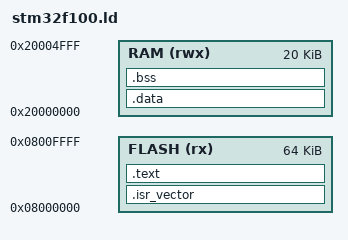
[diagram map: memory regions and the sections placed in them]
ENTRY(Reset_Handler)

MEMORY
{
  FLASH (rx) : ORIGIN = 0x08000000, LENGTH = 64K
  RAM   (rwx): ORIGIN = 0x20000000, LENGTH = 20K
}

_estack = ORIGIN(RAM) + LENGTH(RAM);

SECTIONS
{
  .isr_vector : {
    KEEP(*(.isr_vector))
  } > FLASH

  .text : {
    *(.text*)
    *(.rodata*)
    . = ALIGN(4);
  } > FLASH

  .data : AT(__data_load_start) {
    __data_start = .;
    *(.data*)
    . = ALIGN(4);
    __data_end = .;
  } > RAM

  .bss : {
    __bss_start__ = .;
    *(.bss*)
    *(COMMON)
    . = ALIGN(4);
    __bss_end__ = .;
  } > RAM

  __data_load_start = LOADADDR(.data);
}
